# $root: IP-XACT component
VLNV example.org:mylibrary:$root:1.0

## Address spaces and blocks
cr_4b_mmap.cr_4b: base 'h0, range 'h21a84, width 32

## Registers
Registers are 32-bit, access per field, reset 0x0 unless marked. A register's access mark holds for its fields unless they carry their own. Offsets are from the block's base; lines under a group give offsets from that group; [hi:lo] are bit positions; {n}, {i} and the like mark numbered series; 'fields as' and 'values as' point back to an identical list; <NAME> marks a mode.

## cr_4b_mmap.cr_4b
Base 0x00000000
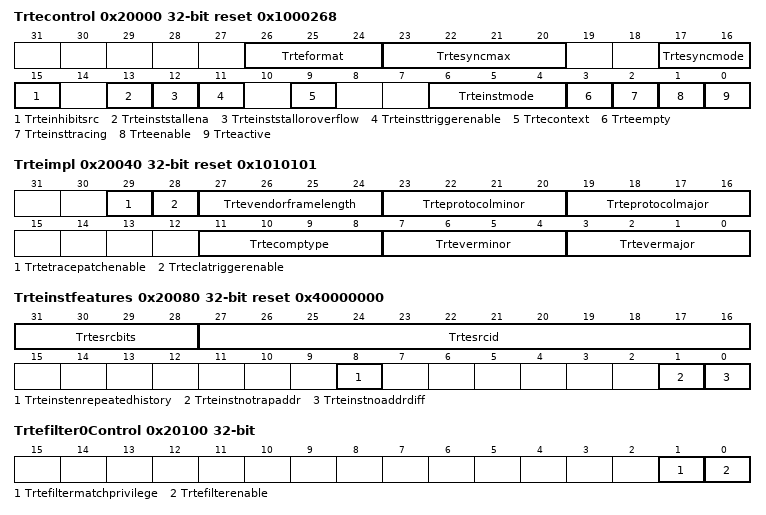
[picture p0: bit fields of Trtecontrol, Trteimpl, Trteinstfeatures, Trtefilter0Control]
0x20000 Trtecontrol reset 0x1000268
  [26:24] Trteformat rw, [23:20] Trtesyncmax rw, [17:16] Trtesyncmode rw, [15] Trteinhibitsrc rw, [13] Trteinststallena rw, [12] Trteinststalloroverflow rw, [11] Trteinsttriggerenable rw, [9] Trtecontext ro, [6:4] Trteinstmode ro, [3] Trteempty ro, [2] Trteinsttracing rw, [1] Trteenable rw, [0] Trteactive rw
0x20040 Trteimpl reset 0x1010101
  [29] Trtetracepatchenable rw — Enable bit for Tracing while in Patch mode
  [28] Trteclatriggerenable rw — Enable bit for consuming CLA external trace action triggers for N-trace start/stop controls
  [27:24] Trtevendorframelength rw — Specify frame length. Frame Length = trTeVendorFrameLength* 64 ; Frame Length should be a multiple of Bank Data Width.
  [23:20] Trteprotocolminor ro
  [19:16] Trteprotocolmajor ro
  [11:8] Trtecomptype ro
  [7:4] Trteverminor ro
  [3:0] Trtevermajor ro
0x20080 Trteinstfeatures reset 0x40000000
  [31:28] Trtesrcbits rw, [27:16] Trtesrcid rw, [8] Trteinstenrepeatedhistory ro, [1] Trteinstnotrapaddr ro, [0] Trteinstnoaddrdiff ro
0x200C0 Trteinstfilters rw
  [15:0] Trteinstfilters
0x20100 Trtefilter0Control rw
  [1] Trtefiltermatchprivilege, [0] Trtefilterenable
0x20140 Trtefilter0Matchinst rw
  [7:0] Trtefiltermatchchoiceprivilege
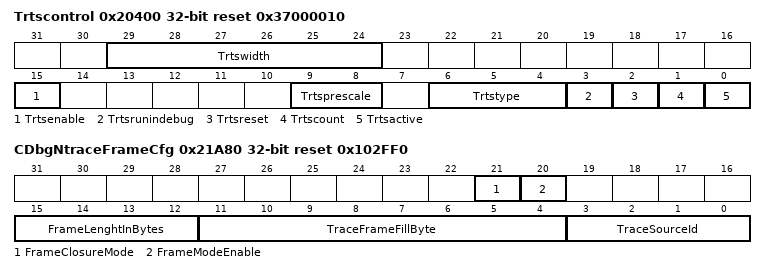
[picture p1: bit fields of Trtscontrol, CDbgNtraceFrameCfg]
0x20400 Trtscontrol reset 0x37000010
  [29:24] Trtswidth ro, [15] Trtsenable rw, [9:8] Trtsprescale ro, [6:4] Trtstype ro, [3] Trtsrunindebug ro, [2] Trtsreset ro, [1] Trtscount ro, [0] Trtsactive rw
0x21A80 CDbgNtraceFrameCfg rw reset 0x102FF0
  [21] FrameClosureMode — Closure Mode: 1: Close frame with a packet no larger than max packet size before any overflow (due to packets crossing frame boundary). 0: Close frame when packets cross boundary. Push back packet crossing frame boundary to packet generator.
  [20] FrameModeEnable — Enable Frame Mode (Frame Mode: Always pack "frame length" number of bytes for trace transmission). If flush to memory is stalled (due to silicon bug), we can have incomplete packets in memory. Frame Mode will help SW decoder to avoid reading incomplete trasnmitted packets. In Frame Mode, SW will get a memory pointer that is aligned to Frame Length. HW will ensure there are no incomplete packets incluced in the region pointed by memory pointer.
  [15:12] FrameLenghtInBytes — Use trDstTe[trDstVendorFrameLength] for Frame Length programming. Register field ZBB-ed.
  [11:4] TraceFrameFillByte — Use "Filler Packet" to align a stream of trace packets within a frame boundary.
  [3:0] TraceSourceId — Trace Source ID (FIXME: Base Address, Tool Issue)
